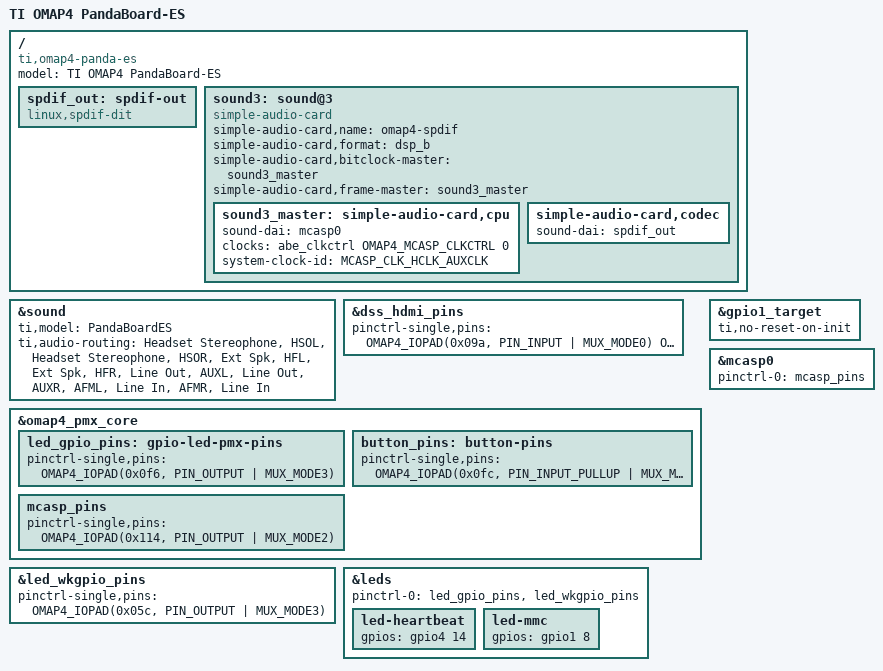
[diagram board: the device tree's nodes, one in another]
// SPDX-License-Identifier: GPL-2.0-only
/*
 * Copyright (C) 2012 Texas Instruments Incorporated - https://www.ti.com/
 */
/dts-v1/;

#include "omap4460.dtsi"
#include "omap4-panda-common.dtsi"
#include <dt-bindings/sound/ti-mcasp.h>

/ {
	model = "TI OMAP4 PandaBoard-ES";
	compatible = "ti,omap4-panda-es", "ti,omap4-panda", "ti,omap4460", "ti,omap4430", "ti,omap4";

	spdif_out: spdif-out {
		#sound-dai-cells = <0>;
		compatible = "linux,spdif-dit";
	};

	sound3: sound@3 {
		compatible = "simple-audio-card";
		simple-audio-card,name = "omap4-spdif";
		simple-audio-card,format = "dsp_b";
		simple-audio-card,bitclock-master = <&sound3_master>;
		simple-audio-card,frame-master = <&sound3_master>;

		status = "okay";

		sound3_master: simple-audio-card,cpu {
			sound-dai = <&mcasp0>;
			clocks = <&abe_clkctrl OMAP4_MCASP_CLKCTRL 0>;
			system-clock-id = <MCASP_CLK_HCLK_AUXCLK>;
		};

		simple-audio-card,codec {
			sound-dai = <&spdif_out>;
		};
	};
};

/* Audio routing is differnet between PandaBoard4430 and PandaBoardES */
&sound {
	ti,model = "PandaBoardES";

	/* Audio routing */
	ti,audio-routing =
		"Headset Stereophone", "HSOL",
		"Headset Stereophone", "HSOR",
		"Ext Spk", "HFL",
		"Ext Spk", "HFR",
		"Line Out", "AUXL",
		"Line Out", "AUXR",
		"AFML", "Line In",
		"AFMR", "Line In";
};

/* PandaboardES has external pullups on SCL & SDA */
&dss_hdmi_pins {
	pinctrl-single,pins = <
		OMAP4_IOPAD(0x09a, PIN_INPUT | MUX_MODE0)		/* hdmi_cec.hdmi_cec */
		OMAP4_IOPAD(0x09c, PIN_INPUT | MUX_MODE0)		/* hdmi_scl.hdmi_scl */
		OMAP4_IOPAD(0x09e, PIN_INPUT | MUX_MODE0)		/* hdmi_sda.hdmi_sda */
		>;
};

&omap4_pmx_core {
	led_gpio_pins: gpio-led-pmx-pins {
		pinctrl-single,pins = <
			OMAP4_IOPAD(0x0f6, PIN_OUTPUT | MUX_MODE3)	/* gpio_110 */
		>;
	};

	button_pins: button-pins {
		pinctrl-single,pins = <
			OMAP4_IOPAD(0x0fc, PIN_INPUT_PULLUP | MUX_MODE3) /* gpio_113 */
		>;
	};

	mcasp_pins: mcasp_pins {
		pinctrl-single,pins = <
			OMAP4_IOPAD(0x114, PIN_OUTPUT | MUX_MODE2) /* abe_dmic_din2.abe_mcasp_axr */
		>;
	};
};

&led_wkgpio_pins {
	pinctrl-single,pins = <
		OMAP4_IOPAD(0x05c, PIN_OUTPUT | MUX_MODE3)	/* gpio_wk8 */
	>;
};

&leds {
	pinctrl-0 = <
		&led_gpio_pins
		&led_wkgpio_pins
	>;

	led-heartbeat {
		gpios = <&gpio4 14 GPIO_ACTIVE_HIGH>;
	};
	led-mmc {
		gpios = <&gpio1 8 GPIO_ACTIVE_HIGH>;
	};
};

&gpio1_target {
	 ti,no-reset-on-init;
};

&mcasp0 {
	#sound-dai-cells = <0>;
	status = "okay";

	pinctrl-0 = <&mcasp_pins>;
	pinctrl-names = "default";
};
